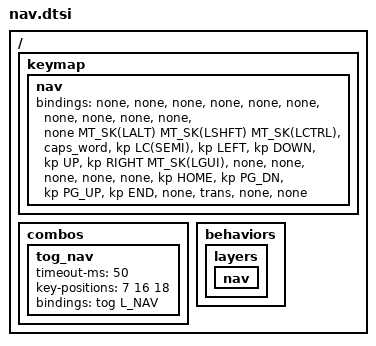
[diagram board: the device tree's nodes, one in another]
// Copyright (c) 2022 The ZMK Contributors
// SPDX-License-Identifier: MIT

#define B_NAV(key) B_LAYER(nav, key)

/ {
    keymap {
        nav {
            bindings = <
        // ╭──────────────┬──────────────┬──────────────┬──────────────┬──────────────╮   ╭──────────────┬──────────────┬──────────────┬──────────────┬──────────────╮
        // │              │              │              │              │              │   │              │              │              │              │              │
             &none          &none          &none          &none          &none              &none          &none          &none          &none          &none
        // ├──────────────┼──────────────┼──────────────┼──────────────┼──────────────┤   ├──────────────┼──────────────┼──────────────┼──────────────┼──────────────┤
        // │              │  ALT         │  SHIFT       │  CONTROL     │              │   │  keynav      │  LEFT        │  DOWN        │  UP          │  RIGHT       │
             &none          MT_SK(LALT)    MT_SK(LSHFT)   MT_SK(LCTRL)   &caps_word         &kp LC(SEMI)   &kp LEFT       &kp DOWN       &kp UP         &kp RIGHT
        // ├──────────────┼──────────────┼──────────────┼──────────────┼──────────────┤   ├──────────────┼──────────────┼──────────────┼──────────────┼──────────────┤
        // │  GUI         │              │              │              │              │   │              │  HOME        │  PAGE DOWN   │  PAGE UP     │  END         │
             MT_SK(LGUI)    &none          &none          &none          &none              &none          &kp HOME       &kp PG_DN      &kp PG_UP      &kp END
        // ╰──────────────┴──────────────┴──────────────┼──────────────┼──────────────┤   ├──────────────┼──────────────┼──────────────┴──────────────┴──────────────╯
        //                                              |              |              |   |              |              |
                                                          &none          &trans             &none          &none
        //                                              ╰──────────────┴──────────────╯   ╰──────────────┴──────────────╯
            >;
        };
    };

    combos {
      tog_nav {
        timeout-ms = <50>;
        key-positions = <7 16 18>;
        bindings = <&tog L_NAV>;
      };
    };

    behaviors {
        layers {
            nav {
            };
        };
    };
};
